# DA1470x register map
Vendor: Dialog; Series: DA1470x; File version: 1.2
CPU: CM33 r0p2, little endian, MPU, FPU, DSP, VTOR, 4 interrupt priority bits
Registers are 32-bit, read-write, reset 0x0 unless marked. A register's access mark holds for its fields unless they carry their own. Offsets are from the block's base; [hi:lo] are bit positions.

## GPADC — GPADC registers
Base 0x50020800
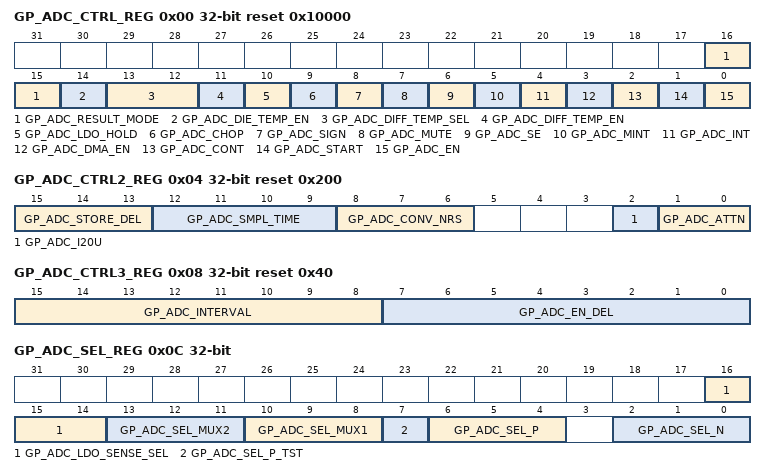
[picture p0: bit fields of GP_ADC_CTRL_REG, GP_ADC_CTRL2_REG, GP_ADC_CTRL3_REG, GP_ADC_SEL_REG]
0x00 GP_ADC_CTRL_REG reset 0x10000 — General Purpose ADC Control Register
  [16:15] GP_ADC_RESULT_MODE — Sample mode 0: Sample extention, the result is aligned on the MSBs. The lowest calculated LSB is extended over the unused bits. 1: Sample truncation, the result is aligned on the 8 LSBs. Any additional accurancy isn't available. 2: Normal mode, the result is aligned on the MSBs. Any unused LSBs are kept zero. 3: N.A.
  [14] GP_ADC_DIE_TEMP_EN — Enables the die-temperature sensor. Output can be measured on GPADC input 4.
  [13:12] GP_ADC_DIFF_TEMP_SEL — 0= Gnd, 1 =sensor near radio, 2 =sensor near charger, 3 =sensor near bandgap with sensors disabled (GP_ADC_DIFF_TEMP_EN = 0) :0 = GND 1 = Z, 2= V(ntc) from charger, 3 = V(temp) from charger
  [11] GP_ADC_DIFF_TEMP_EN — 1: Enable the on-chip temperature sensors
  [10] GP_ADC_LDO_HOLD — 0: GPADC LDO tracking bandgap reference 1: GPADC LDO hold sampled bandgap reference
  [9] GP_ADC_CHOP — 0: Chopper mode off 1: Chopper mode enabled. Takes two samples with opposite GP_ADC_SIGN to cancel the internal offset voltage of the ADC; Highly recommended for DC-measurements.
  [8] GP_ADC_SIGN — 0: Default 1: Conversion with opposite sign at input and output to cancel out the internal offset of the ADC and low-frequency
  [7] GP_ADC_MUTE — 0: Normal operation 1: Mute ADC input. Takes sample at mid-scale (to dertermine the internal offset and/or noise of the ADC with regards to VDD_REF which is also sampled by the ADC).
  [6] GP_ADC_SE — 0: Differential mode 1: Single ended mode
  [5] GP_ADC_MINT — 0: Disable (mask) GP_ADC_INT. 1: Enable GP_ADC_INT to ICU.
  [4] GP_ADC_INT ro — 1: AD conversion ready and has generated an interrupt. Must be cleared by writing any value to GP_ADC_CLEAR_INT_REG.
  [3] GP_ADC_DMA_EN — 0: DMA functionality disabled 1: DMA functionality enabled
  [2] GP_ADC_CONT — 0: Manual ADC mode, a single result will be generated after setting the GP_ADC_START bit. 1: Continuous ADC mode, new ADC results will be constantly stored in GP_ADC_RESULT_REG. Still GP_ADC_START has to be set to start the execution. The time between conversions is configurable with GP_ADC_INTERVAL.
  [1] GP_ADC_START — 0: ADC conversion ready. 1: If a 1 is written, the ADC starts a conversion. After the conversion this bit will be set to 0 and the GP_ADC_INT bit will be set. It is not allowed to write this bit while it is not (yet) zero.
  [0] GP_ADC_EN — 0: LDO is off and ADC is disabled.. 1: LDO is turned on and afterwards the ADC is enabled.
0x04 GP_ADC_CTRL2_REG reset 0x200 — General Purpose ADC Second Control Register
  [15:13] GP_ADC_STORE_DEL — 0: Data is stored after handshake synchronisation 1: Data is stored 2 ADC_CLK cycles after internal start trigger 7: Data is stored 8 ADC_CLK cycles after internal start trigger
  [12:9] GP_ADC_SMPL_TIME — 0: The sample time (switch is closed) is two ADC_CLK cycles 1: The sample time is 1*8 ADC_CLK cycles 2: The sample time is 2*8 ADC_CLK cycles 15: The sample time is 15*8 ADC_CLK cycles
  [8:6] GP_ADC_CONV_NRS — 0: 1 sample is taken or 2 in case ADC_CHOP is active. 1: 2 samples are taken. 2: 4 samples are taken. 7: 128 samples are taken.
  [2] GP_ADC_I20U — 1: Adds 20uA constant load current at the ADC LDO to minimize ripple on the reference voltage of the ADC.
  [1:0] GP_ADC_ATTN — 0: No attenuator (input voltages up to 0.9V allowed) 1: Enabling 2x attenuator (input voltages up to 1.8V allowed) 2: Enabling 3x attenuator (input voltages up to 2.7V allowed) 3: Enabling 4x attenuator (input voltages up to 3.6V allowed) Enabling the attenuator requires a longer sampling time.
0x08 GP_ADC_CTRL3_REG reset 0x40 — General Purpose ADC Third Control Register
  [15:8] GP_ADC_INTERVAL — Defines the interval between two ADC conversions in case GP_ADC_CONT is set. 0: No extra delay between two conversions. 1: 1.024 ms interval between two conversions. 2: 2.048 ms interval between two conversions. 255: 261.12 ms interval between two conversions.
  [7:0] GP_ADC_EN_DEL — Defines the delay for enabling the ADC after enabling the LDO. 0: Not allowed 1: 4x ADC_CLK period. n: n*4x ADC_CLK period.
0x0C GP_ADC_SEL_REG — General Purpose ADC Input Selection Register
  [16:14] GP_ADC_LDO_SENSE_SEL — Enable and select the current sensing logic for one of the LDO's 0: LDO current sense disabled 1: Sense current of LDO_SUPPLY_VBUS (V33) 2: Sense current of LDO_1V4 3: Sense current of LDO_1V8 4: Sense current of LDO_CORE (VDD1V2) 5: Sense current of LDO_1V8P 6: Sense current of LDO_SUPPLY_VBAT (V33) 7: Reserved
  [13:11] GP_ADC_SEL_MUX2 — 0: No rail selected 1: V18P 2: V18 3: V14 4: V12 5: VSYS monitor 6: VBUS monitor 7: VBAT monitor
  [10:8] GP_ADC_SEL_MUX1 — 0: No rail selected 1: NC 2: Reserved 3: I_sense_bus 4: Reserved 5: V30 6: VMIPI 7: V18F
  [7] GP_ADC_SEL_P_TST — When set to 1, GP_ADC_SEL_P selection becomes 0: VSSA 1: VDDA_CONT 2: RF_TEST_OUT[0] 3: RF_TEST_OUT[1] 4: RF_TEST_IN[0] 5: RF_TEST_IN[1] 6: ANA_TEST 7: Bandgap Current sensing
  [6:4] GP_ADC_SEL_P — ADC positive input selection. 0: ADC0 (P1[0]) 1: ADC1 (P1[1]) 2: ADC2 (P1[2]) 3: ADC3 (P0[10]) 4: Temperature Sensor 5: VBAT_HIGH 6: VBAT_LOW 7: VDDD
  [2:0] GP_ADC_SEL_N — ADC negative input selection. Differential only (GP_ADC_SE=0). 0: ADC0 (P1[0]) 1: ADC1 (P1[1]) 2: ADC2 (P1[2]) 3: ADC3 (P0[10]) All other combinations are reserved.
0x10 GP_ADC_OFFP_REG reset 0x200 — General Purpose ADC Positive Offset Register
  [9:0] GP_ADC_OFFP — Offset adjust of 'positive' array of ADC-network (effective if "GP_ADC_SE=0", or "GP_ADC_SE=1 AND GP_ADC_SIGN=0 OR GP_ADC_CHOP=1")
0x14 GP_ADC_OFFN_REG reset 0x200 — General Purpose ADC Negative Offset Register
  [9:0] GP_ADC_OFFN — Offset adjust of 'negative' array of ADC-network (effective if "GP_ADC_SE=0", or "GP_ADC_SE=1 AND GP_ADC_SIGN=1 OR GP_ADC_CHOP=1")
0x18 GP_ADC_TRIM_REG reset 0x3 — General Purpose ADC Trim Register
  [2:0] GP_ADC_LDO_LEVEL — GPADC LDO level 0: 825mV 1: 850mV 2: 875mV 3: 900mV (reset) 4: 925mV (default) 5: 950mV 6: 975mV 7:1000mV
0x1C GP_ADC_CLEAR_INT_REG — General Purpose ADC Clear Interrupt Register
  [15:0] GP_ADC_CLR_INT wo — Writing any value to this register will clear the ADC_INT interrupt. Reading returns 0.
0x20 GP_ADC_RESULT_REG — General Purpose ADC Result Register
  [15:0] GP_ADC_VAL ro — Returns the 10 up to 16 bits linear value of the last AD conversion. The upper 10 bits are always valid, the lower 6 bits are only valid in case oversampling has been applied. Two samples results in one extra bit and 64 samples results in six extra bits.
